# MKL28Z7 register map
Vendor: Freescale Semiconductor, Inc.; Series: Kinetis_L; File version: 1.6
CPU: CM0PLUS r0p0, little endian, no MPU, no FPU, VTOR, 2 interrupt priority bits
Registers are 32-bit, read-write, reset 0x0 unless marked. A register's access mark holds for its fields unless they carry their own. Offsets are from the block's base; [hi:lo] are bit positions; {n}, {i} and the like mark numbered series; 'fields as' and 'values as' point back to an identical list.

## NVIC0 — Nested Vectored Interrupt Controller
Base 0xE000E100
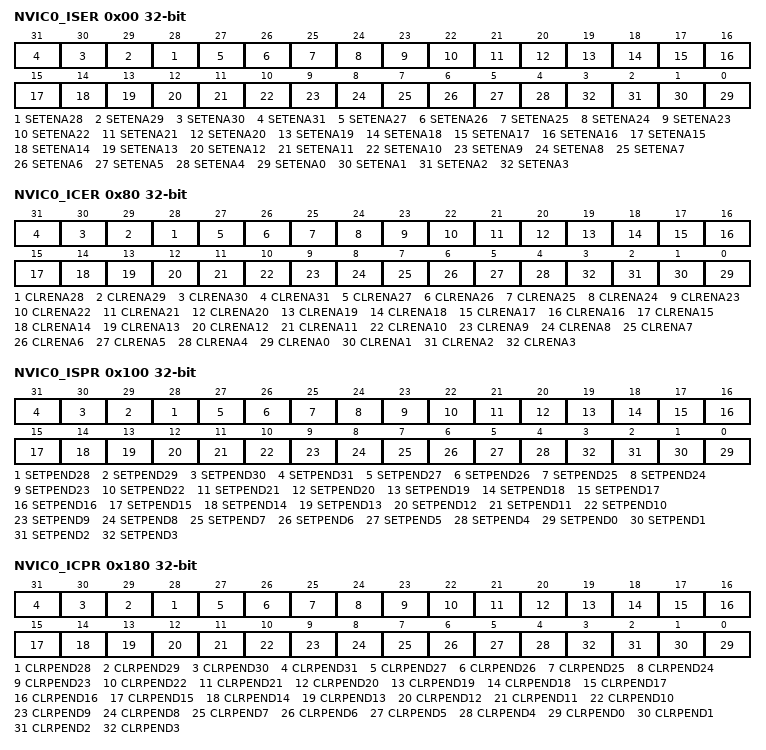
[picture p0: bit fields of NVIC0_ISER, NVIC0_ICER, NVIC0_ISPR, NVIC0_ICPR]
0x00 NVIC0_ISER — Interrupt Set Enable Register
  [n] SETENA{n} (n=28..31) — INTMUX0 channel {n-28} interrupt interrupt set-enable bit
    0=write: no effect; read: INTMUX0 channel {n-28} interrupt interrupt disabled; 1=write: enable INTMUX0 channel {n-28} interrupt interrupt; read: INTMUX0 channel {n-28} interrupt interrupt enabled
  [27] SETENA27 — RTC seconds interrupt set-enable bit
    0=write: no effect; read: RTC seconds interrupt disabled; 1=write: enable RTC seconds interrupt; read: RTC seconds interrupt enabled
  [26] SETENA26 — Low-Power Timer interrupt set-enable bit
    0=write: no effect; read: Low-Power Timer interrupt disabled; 1=write: enable Low-Power Timer interrupt; read: Low-Power Timer interrupt enabled
  [25] SETENA25 — Analog-to-Digital Converter 0 interrupt set-enable bit
    0=write: no effect; read: Analog-to-Digital Converter 0 interrupt disabled; 1=write: enable Analog-to-Digital Converter 0 interrupt; read: Analog-to-Digital Converter 0 interrupt enabled
  [24] SETENA24 — Universal Serial Bus interrupt set-enable bit
    0=write: no effect; read: Universal Serial Bus interrupt disabled; 1=write: enable Universal Serial Bus interrupt; read: Universal Serial Bus interrupt enabled
  [23] SETENA23 — Integrated interchip sound 0 interrupt set-enable bit
    0=write: no effect; read: Integrated interchip sound 0 interrupt disabled; 1=write: enable Integrated interchip sound 0 interrupt; read: Integrated interchip sound 0 interrupt enabled
  [22] SETENA22 — Low Leakage Wakeup 0 interrupt set-enable bit
    0=write: no effect; read: Low Leakage Wakeup 0 interrupt disabled; 1=write: enable Low Leakage Wakeup 0 interrupt; read: Low Leakage Wakeup 0 interrupt enabled
  [21] SETENA21 — PORTE Pin detect interrupt set-enable bit
    0=write: no effect; read: PORTE Pin detect interrupt disabled; 1=write: enable PORTE Pin detect interrupt; read: PORTE Pin detect interrupt enabled
  [20] SETENA20 — PORTD Pin detect interrupt set-enable bit
    0=write: no effect; read: PORTD Pin detect interrupt disabled; 1=write: enable PORTD Pin detect interrupt; read: PORTD Pin detect interrupt enabled
  [19] SETENA19 — PORTC Pin detect interrupt set-enable bit
    0=write: no effect; read: PORTC Pin detect interrupt disabled; 1=write: enable PORTC Pin detect interrupt; read: PORTC Pin detect interrupt enabled
  [18] SETENA18 — PORTB Pin detect interrupt set-enable bit
    0=write: no effect; read: PORTB Pin detect interrupt disabled; 1=write: enable PORTB Pin detect interrupt; read: PORTB Pin detect interrupt enabled
  [17] SETENA17 — PORTA Pin detect interrupt set-enable bit
    0=write: no effect; read: PORTA Pin detect interrupt disabled; 1=write: enable PORTA Pin detect interrupt; read: PORTA Pin detect interrupt enabled
  [16] SETENA16 — Reserved iv 32 interrupt set-enable bit
    0=write: no effect; read: Reserved iv 32 interrupt disabled; 1=write: enable Reserved iv 32 interrupt; read: Reserved iv 32 interrupt enabled
  [15] SETENA15 — Inter-Integrated Circuit 0 interrupt set-enable bit
    0=write: no effect; read: Inter-Integrated Circuit 0 interrupt disabled; 1=write: enable Inter-Integrated Circuit 0 interrupt; read: Inter-Integrated Circuit 0 interrupt enabled
  [14] SETENA14 — Inter-Integrated Circuit 0 interrupt set-enable bit
    values as SETENA15
  [13] SETENA13 — LPUART1 status and error interrupt set-enable bit
    0=write: no effect; read: LPUART1 status and error interrupt disabled; 1=write: enable LPUART1 status and error interrupt; read: LPUART1 status and error interrupt enabled
  [12] SETENA12 — LPUART0 status and error interrupt set-enable bit
    0=write: no effect; read: LPUART0 status and error interrupt disabled; 1=write: enable LPUART0 status and error interrupt; read: LPUART0 status and error interrupt enabled
  [11] SETENA11 — Serial Peripheral Interface 1 interrupt set-enable bit
    0=write: no effect; read: Serial Peripheral Interface 1 interrupt disabled; 1=write: enable Serial Peripheral Interface 1 interrupt; read: Serial Peripheral Interface 1 interrupt enabled
  [10] SETENA10 — Serial Peripheral Interface 0 interrupt set-enable bit
    0=write: no effect; read: Serial Peripheral Interface 0 interrupt disabled; 1=write: enable Serial Peripheral Interface 0 interrupt; read: Serial Peripheral Interface 0 interrupt enabled
  [9] SETENA9 — Low Power Periodic Interrupt Timer interrupt set-enable bit
    0=write: no effect; read: Low Power Periodic Interrupt Timer interrupt disabled; 1=write: enable Low Power Periodic Interrupt Timer interrupt; read: Low Power Periodic Interrupt Timer interrupt enabled
  [8] SETENA8 — Timer/PWM module 2 interrupt set-enable bit
    0=write: no effect; read: Timer/PWM module 2 interrupt disabled; 1=write: enable Timer/PWM module 2 interrupt; read: Timer/PWM module 2 interrupt enabled
  [7] SETENA7 — Timer/PWM module 1 interrupt set-enable bit
    0=write: no effect; read: Timer/PWM module 1 interrupt disabled; 1=write: enable Timer/PWM module 1 interrupt; read: Timer/PWM module 1 interrupt enabled
  [6] SETENA6 — Timer/PWM module 0 interrupt set-enable bit
    0=write: no effect; read: Timer/PWM module 0 interrupt disabled; 1=write: enable Timer/PWM module 0 interrupt; read: Timer/PWM module 0 interrupt enabled
  [5] SETENA5 — FLEXIO0 interrupt set-enable bit
    0=write: no effect; read: FLEXIO0 interrupt disabled; 1=write: enable FLEXIO0 interrupt; read: FLEXIO0 interrupt enabled
  [4] SETENA4 — CTI0 or DMA0 error interrupt set-enable bit
    0=write: no effect; read: CTI0 or DMA0 error interrupt disabled; 1=write: enable CTI0 or DMA0 error interrupt; read: CTI0 or DMA0 error interrupt enabled
  [n] SETENA{n} (n=0..3) — DMA0 channel {n}/{n+4} transfer complete interrupt set-enable bit
    0=write: no effect; read: DMA0 channel {n}/{n+4} transfer complete interrupt disabled; 1=write: enable DMA0 channel {n}/{n+4} transfer complete interrupt; read: DMA0 channel {n}/{n+4} transfer complete interrupt enabled
0x80 NVIC0_ICER — Interrupt Clear Enable Register
  [n] CLRENA{n} (n=28..31) — INTMUX0 channel {n-28} interrupt interrupt clear-enable bit
    0=write: no effect; read: INTMUX0 channel {n-28} interrupt interrupt disabled; 1=write: disable INTMUX0 channel {n-28} interrupt interrupt; read: INTMUX0 channel {n-28} interrupt interrupt enabled
  [27] CLRENA27 — RTC seconds interrupt clear-enable bit
    0=write: no effect; read: RTC seconds interrupt disabled; 1=write: disable RTC seconds interrupt; read: RTC seconds interrupt enabled
  [26] CLRENA26 — Low-Power Timer interrupt clear-enable bit
    0=write: no effect; read: Low-Power Timer interrupt disabled; 1=write: disable Low-Power Timer interrupt; read: Low-Power Timer interrupt enabled
  [25] CLRENA25 — Analog-to-Digital Converter 0 interrupt clear-enable bit
    0=write: no effect; read: Analog-to-Digital Converter 0 interrupt disabled; 1=write: disable Analog-to-Digital Converter 0 interrupt; read: Analog-to-Digital Converter 0 interrupt enabled
  [24] CLRENA24 — Universal Serial Bus interrupt clear-enable bit
    0=write: no effect; read: Universal Serial Bus interrupt disabled; 1=write: disable Universal Serial Bus interrupt; read: Universal Serial Bus interrupt enabled
  [23] CLRENA23 — Integrated interchip sound 0 interrupt clear-enable bit
    0=write: no effect; read: Integrated interchip sound 0 interrupt disabled; 1=write: disable Integrated interchip sound 0 interrupt; read: Integrated interchip sound 0 interrupt enabled
  [22] CLRENA22 — Low Leakage Wakeup 0 interrupt clear-enable bit
    0=write: no effect; read: Low Leakage Wakeup 0 interrupt disabled; 1=write: disable Low Leakage Wakeup 0 interrupt; read: Low Leakage Wakeup 0 interrupt enabled
  [21] CLRENA21 — PORTE Pin detect interrupt clear-enable bit
    0=write: no effect; read: PORTE Pin detect interrupt disabled; 1=write: disable PORTE Pin detect interrupt; read: PORTE Pin detect interrupt enabled
  [20] CLRENA20 — PORTD Pin detect interrupt clear-enable bit
    0=write: no effect; read: PORTD Pin detect interrupt disabled; 1=write: disable PORTD Pin detect interrupt; read: PORTD Pin detect interrupt enabled
  [19] CLRENA19 — PORTC Pin detect interrupt clear-enable bit
    0=write: no effect; read: PORTC Pin detect interrupt disabled; 1=write: disable PORTC Pin detect interrupt; read: PORTC Pin detect interrupt enabled
  [18] CLRENA18 — PORTB Pin detect interrupt clear-enable bit
    0=write: no effect; read: PORTB Pin detect interrupt disabled; 1=write: disable PORTB Pin detect interrupt; read: PORTB Pin detect interrupt enabled
  [17] CLRENA17 — PORTA Pin detect interrupt clear-enable bit
    0=write: no effect; read: PORTA Pin detect interrupt disabled; 1=write: disable PORTA Pin detect interrupt; read: PORTA Pin detect interrupt enabled
  [16] CLRENA16 — Reserved iv 32 interrupt clear-enable bit
    0=write: no effect; read: Reserved iv 32 interrupt disabled; 1=write: disable Reserved iv 32 interrupt; read: Reserved iv 32 interrupt enabled
  [15] CLRENA15 — Inter-Integrated Circuit 0 interrupt clear-enable bit
    0=write: no effect; read: Inter-Integrated Circuit 0 interrupt disabled; 1=write: disable Inter-Integrated Circuit 0 interrupt; read: Inter-Integrated Circuit 0 interrupt enabled
  [14] CLRENA14 — Inter-Integrated Circuit 0 interrupt clear-enable bit
    values as CLRENA15
  [13] CLRENA13 — LPUART1 status and error interrupt clear-enable bit
    0=write: no effect; read: LPUART1 status and error interrupt disabled; 1=write: disable LPUART1 status and error interrupt; read: LPUART1 status and error interrupt enabled
  [12] CLRENA12 — LPUART0 status and error interrupt clear-enable bit
    0=write: no effect; read: LPUART0 status and error interrupt disabled; 1=write: disable LPUART0 status and error interrupt; read: LPUART0 status and error interrupt enabled
  [11] CLRENA11 — Serial Peripheral Interface 1 interrupt clear-enable bit
    0=write: no effect; read: Serial Peripheral Interface 1 interrupt disabled; 1=write: disable Serial Peripheral Interface 1 interrupt; read: Serial Peripheral Interface 1 interrupt enabled
  [10] CLRENA10 — Serial Peripheral Interface 0 interrupt clear-enable bit
    0=write: no effect; read: Serial Peripheral Interface 0 interrupt disabled; 1=write: disable Serial Peripheral Interface 0 interrupt; read: Serial Peripheral Interface 0 interrupt enabled
  [9] CLRENA9 — Low Power Periodic Interrupt Timer interrupt clear-enable bit
    0=write: no effect; read: Low Power Periodic Interrupt Timer interrupt disabled; 1=write: disable Low Power Periodic Interrupt Timer interrupt; read: Low Power Periodic Interrupt Timer interrupt enabled
  [8] CLRENA8 — Timer/PWM module 2 interrupt clear-enable bit
    0=write: no effect; read: Timer/PWM module 2 interrupt disabled; 1=write: disable Timer/PWM module 2 interrupt; read: Timer/PWM module 2 interrupt enabled
  [7] CLRENA7 — Timer/PWM module 1 interrupt clear-enable bit
    0=write: no effect; read: Timer/PWM module 1 interrupt disabled; 1=write: disable Timer/PWM module 1 interrupt; read: Timer/PWM module 1 interrupt enabled
  [6] CLRENA6 — Timer/PWM module 0 interrupt clear-enable bit
    0=write: no effect; read: Timer/PWM module 0 interrupt disabled; 1=write: disable Timer/PWM module 0 interrupt; read: Timer/PWM module 0 interrupt enabled
  [5] CLRENA5 — FLEXIO0 interrupt clear-enable bit
    0=write: no effect; read: FLEXIO0 interrupt disabled; 1=write: disable FLEXIO0 interrupt; read: FLEXIO0 interrupt enabled
  [4] CLRENA4 — CTI0 or DMA0 error interrupt clear-enable bit
    0=write: no effect; read: CTI0 or DMA0 error interrupt disabled; 1=write: disable CTI0 or DMA0 error interrupt; read: CTI0 or DMA0 error interrupt enabled
  [n] CLRENA{n} (n=0..3) — DMA0 channel {n}/{n+4} transfer complete interrupt clear-enable bit
    0=write: no effect; read: DMA0 channel {n}/{n+4} transfer complete interrupt disabled; 1=write: disable DMA0 channel {n}/{n+4} transfer complete interrupt; read: DMA0 channel {n}/{n+4} transfer complete interrupt enabled
0x100 NVIC0_ISPR — Interrupt Set Pending Register
  [n] SETPEND{n} (n=28..31) — INTMUX0 channel {n-28} interrupt interrupt set-pending bit
    0=write: no effect; read: INTMUX0 channel {n-28} interrupt interrupt is not pending; 1=write: changes the INTMUX0 channel {n-28} interrupt interrupt state to pending; read: INTMUX0 channel {n-28} interrupt interrupt is pending
  [27] SETPEND27 — RTC seconds interrupt set-pending bit
    0=write: no effect; read: RTC seconds interrupt is not pending; 1=write: changes the RTC seconds interrupt state to pending; read: RTC seconds interrupt is pending
  [26] SETPEND26 — Low-Power Timer interrupt set-pending bit
    0=write: no effect; read: Low-Power Timer interrupt is not pending; 1=write: changes the Low-Power Timer interrupt state to pending; read: Low-Power Timer interrupt is pending
  [25] SETPEND25 — Analog-to-Digital Converter 0 interrupt set-pending bit
    0=write: no effect; read: Analog-to-Digital Converter 0 interrupt is not pending; 1=write: changes the Analog-to-Digital Converter 0 interrupt state to pending; read: Analog-to-Digital Converter 0 interrupt is pending
  [24] SETPEND24 — Universal Serial Bus interrupt set-pending bit
    0=write: no effect; read: Universal Serial Bus interrupt is not pending; 1=write: changes the Universal Serial Bus interrupt state to pending; read: Universal Serial Bus interrupt is pending
  [23] SETPEND23 — Integrated interchip sound 0 interrupt set-pending bit
    0=write: no effect; read: Integrated interchip sound 0 interrupt is not pending; 1=write: changes the Integrated interchip sound 0 interrupt state to pending; read: Integrated interchip sound 0 interrupt is pending
  [22] SETPEND22 — Low Leakage Wakeup 0 interrupt set-pending bit
    0=write: no effect; read: Low Leakage Wakeup 0 interrupt is not pending; 1=write: changes the Low Leakage Wakeup 0 interrupt state to pending; read: Low Leakage Wakeup 0 interrupt is pending
  [21] SETPEND21 — PORTE Pin detect interrupt set-pending bit
    0=write: no effect; read: PORTE Pin detect interrupt is not pending; 1=write: changes the PORTE Pin detect interrupt state to pending; read: PORTE Pin detect interrupt is pending
  [20] SETPEND20 — PORTD Pin detect interrupt set-pending bit
    0=write: no effect; read: PORTD Pin detect interrupt is not pending; 1=write: changes the PORTD Pin detect interrupt state to pending; read: PORTD Pin detect interrupt is pending
  [19] SETPEND19 — PORTC Pin detect interrupt set-pending bit
    0=write: no effect; read: PORTC Pin detect interrupt is not pending; 1=write: changes the PORTC Pin detect interrupt state to pending; read: PORTC Pin detect interrupt is pending
  [18] SETPEND18 — PORTB Pin detect interrupt set-pending bit
    0=write: no effect; read: PORTB Pin detect interrupt is not pending; 1=write: changes the PORTB Pin detect interrupt state to pending; read: PORTB Pin detect interrupt is pending
  [17] SETPEND17 — PORTA Pin detect interrupt set-pending bit
    0=write: no effect; read: PORTA Pin detect interrupt is not pending; 1=write: changes the PORTA Pin detect interrupt state to pending; read: PORTA Pin detect interrupt is pending
  [16] SETPEND16 — Reserved iv 32 interrupt set-pending bit
    0=write: no effect; read: Reserved iv 32 interrupt is not pending; 1=write: changes the Reserved iv 32 interrupt state to pending; read: Reserved iv 32 interrupt is pending
  [15] SETPEND15 — Inter-Integrated Circuit 0 interrupt set-pending bit
    0=write: no effect; read: Inter-Integrated Circuit 0 interrupt is not pending; 1=write: changes the Inter-Integrated Circuit 0 interrupt state to pending; read: Inter-Integrated Circuit 0 interrupt is pending
  [14] SETPEND14 — Inter-Integrated Circuit 0 interrupt set-pending bit
    values as SETPEND15
  [13] SETPEND13 — LPUART1 status and error interrupt set-pending bit
    0=write: no effect; read: LPUART1 status and error interrupt is not pending; 1=write: changes the LPUART1 status and error interrupt state to pending; read: LPUART1 status and error interrupt is pending
  [12] SETPEND12 — LPUART0 status and error interrupt set-pending bit
    0=write: no effect; read: LPUART0 status and error interrupt is not pending; 1=write: changes the LPUART0 status and error interrupt state to pending; read: LPUART0 status and error interrupt is pending
  [11] SETPEND11 — Serial Peripheral Interface 1 interrupt set-pending bit
    0=write: no effect; read: Serial Peripheral Interface 1 interrupt is not pending; 1=write: changes the Serial Peripheral Interface 1 interrupt state to pending; read: Serial Peripheral Interface 1 interrupt is pending
  [10] SETPEND10 — Serial Peripheral Interface 0 interrupt set-pending bit
    0=write: no effect; read: Serial Peripheral Interface 0 interrupt is not pending; 1=write: changes the Serial Peripheral Interface 0 interrupt state to pending; read: Serial Peripheral Interface 0 interrupt is pending
  [9] SETPEND9 — Low Power Periodic Interrupt Timer interrupt set-pending bit
    0=write: no effect; read: Low Power Periodic Interrupt Timer interrupt is not pending; 1=write: changes the Low Power Periodic Interrupt Timer interrupt state to pending; read: Low Power Periodic Interrupt Timer interrupt is pending
  [8] SETPEND8 — Timer/PWM module 2 interrupt set-pending bit
    0=write: no effect; read: Timer/PWM module 2 interrupt is not pending; 1=write: changes the Timer/PWM module 2 interrupt state to pending; read: Timer/PWM module 2 interrupt is pending
  [7] SETPEND7 — Timer/PWM module 1 interrupt set-pending bit
    0=write: no effect; read: Timer/PWM module 1 interrupt is not pending; 1=write: changes the Timer/PWM module 1 interrupt state to pending; read: Timer/PWM module 1 interrupt is pending
  [6] SETPEND6 — Timer/PWM module 0 interrupt set-pending bit
    0=write: no effect; read: Timer/PWM module 0 interrupt is not pending; 1=write: changes the Timer/PWM module 0 interrupt state to pending; read: Timer/PWM module 0 interrupt is pending
  [5] SETPEND5 — FLEXIO0 interrupt set-pending bit
    0=write: no effect; read: FLEXIO0 interrupt is not pending; 1=write: changes the FLEXIO0 interrupt state to pending; read: FLEXIO0 interrupt is pending
  [4] SETPEND4 — CTI0 or DMA0 error interrupt set-pending bit
    0=write: no effect; read: CTI0 or DMA0 error interrupt is not pending; 1=write: changes the CTI0 or DMA0 error interrupt state to pending; read: CTI0 or DMA0 error interrupt is pending
  [n] SETPEND{n} (n=0..3) — DMA0 channel {n}/{n+4} transfer complete interrupt set-pending bit
    0=write: no effect; read: DMA0 channel {n}/{n+4} transfer complete interrupt is not pending; 1=write: changes the DMA0 channel {n}/{n+4} transfer complete interrupt state to pending; read: DMA0 channel {n}/{n+4} transfer complete interrupt is pending
0x180 NVIC0_ICPR — Interrupt Clear Pending Register
  [n] CLRPEND{n} (n=28..31) — INTMUX0 channel {n-28} interrupt interrupt clear-pending bit
    0=write: no effect; read: INTMUX0 channel {n-28} interrupt interrupt is not pending; 1=write: removes pending state from the INTMUX0 channel {n-28} interrupt interrupt; read: INTMUX0 channel {n-28} interrupt interrupt is pending
  [27] CLRPEND27 — RTC seconds interrupt clear-pending bit
    0=write: no effect; read: RTC seconds interrupt is not pending; 1=write: removes pending state from the RTC seconds interrupt; read: RTC seconds interrupt is pending
  [26] CLRPEND26 — Low-Power Timer interrupt clear-pending bit
    0=write: no effect; read: Low-Power Timer interrupt is not pending; 1=write: removes pending state from the Low-Power Timer interrupt; read: Low-Power Timer interrupt is pending
  [25] CLRPEND25 — Analog-to-Digital Converter 0 interrupt clear-pending bit
    0=write: no effect; read: Analog-to-Digital Converter 0 interrupt is not pending; 1=write: removes pending state from the Analog-to-Digital Converter 0 interrupt; read: Analog-to-Digital Converter 0 interrupt is pending
  [24] CLRPEND24 — Universal Serial Bus interrupt clear-pending bit
    0=write: no effect; read: Universal Serial Bus interrupt is not pending; 1=write: removes pending state from the Universal Serial Bus interrupt; read: Universal Serial Bus interrupt is pending
  [23] CLRPEND23 — Integrated interchip sound 0 interrupt clear-pending bit
    0=write: no effect; read: Integrated interchip sound 0 interrupt is not pending; 1=write: removes pending state from the Integrated interchip sound 0 interrupt; read: Integrated interchip sound 0 interrupt is pending
  [22] CLRPEND22 — Low Leakage Wakeup 0 interrupt clear-pending bit
    0=write: no effect; read: Low Leakage Wakeup 0 interrupt is not pending; 1=write: removes pending state from the Low Leakage Wakeup 0 interrupt; read: Low Leakage Wakeup 0 interrupt is pending
  [21] CLRPEND21 — PORTE Pin detect interrupt clear-pending bit
    0=write: no effect; read: PORTE Pin detect interrupt is not pending; 1=write: removes pending state from the PORTE Pin detect interrupt; read: PORTE Pin detect interrupt is pending
  [20] CLRPEND20 — PORTD Pin detect interrupt clear-pending bit
    0=write: no effect; read: PORTD Pin detect interrupt is not pending; 1=write: removes pending state from the PORTD Pin detect interrupt; read: PORTD Pin detect interrupt is pending
  [19] CLRPEND19 — PORTC Pin detect interrupt clear-pending bit
    0=write: no effect; read: PORTC Pin detect interrupt is not pending; 1=write: removes pending state from the PORTC Pin detect interrupt; read: PORTC Pin detect interrupt is pending
  [18] CLRPEND18 — PORTB Pin detect interrupt clear-pending bit
    0=write: no effect; read: PORTB Pin detect interrupt is not pending; 1=write: removes pending state from the PORTB Pin detect interrupt; read: PORTB Pin detect interrupt is pending
  [17] CLRPEND17 — PORTA Pin detect interrupt clear-pending bit
    0=write: no effect; read: PORTA Pin detect interrupt is not pending; 1=write: removes pending state from the PORTA Pin detect interrupt; read: PORTA Pin detect interrupt is pending
  [16] CLRPEND16 — Reserved iv 32 interrupt clear-pending bit
    0=write: no effect; read: Reserved iv 32 interrupt is not pending; 1=write: removes pending state from the Reserved iv 32 interrupt; read: Reserved iv 32 interrupt is pending
  [15] CLRPEND15 — Inter-Integrated Circuit 0 interrupt clear-pending bit
    0=write: no effect; read: Inter-Integrated Circuit 0 interrupt is not pending; 1=write: removes pending state from the Inter-Integrated Circuit 0 interrupt; read: Inter-Integrated Circuit 0 interrupt is pending
  [14] CLRPEND14 — Inter-Integrated Circuit 0 interrupt clear-pending bit
    values as CLRPEND15
  [13] CLRPEND13 — LPUART1 status and error interrupt clear-pending bit
    0=write: no effect; read: LPUART1 status and error interrupt is not pending; 1=write: removes pending state from the LPUART1 status and error interrupt; read: LPUART1 status and error interrupt is pending
  [12] CLRPEND12 — LPUART0 status and error interrupt clear-pending bit
    0=write: no effect; read: LPUART0 status and error interrupt is not pending; 1=write: removes pending state from the LPUART0 status and error interrupt; read: LPUART0 status and error interrupt is pending
  [11] CLRPEND11 — Serial Peripheral Interface 1 interrupt clear-pending bit
    0=write: no effect; read: Serial Peripheral Interface 1 interrupt is not pending; 1=write: removes pending state from the Serial Peripheral Interface 1 interrupt; read: Serial Peripheral Interface 1 interrupt is pending
  [10] CLRPEND10 — Serial Peripheral Interface 0 interrupt clear-pending bit
    0=write: no effect; read: Serial Peripheral Interface 0 interrupt is not pending; 1=write: removes pending state from the Serial Peripheral Interface 0 interrupt; read: Serial Peripheral Interface 0 interrupt is pending
  [9] CLRPEND9 — Low Power Periodic Interrupt Timer interrupt clear-pending bit
    0=write: no effect; read: Low Power Periodic Interrupt Timer interrupt is not pending; 1=write: removes pending state from the Low Power Periodic Interrupt Timer interrupt; read: Low Power Periodic Interrupt Timer interrupt is pending
  [8] CLRPEND8 — Timer/PWM module 2 interrupt clear-pending bit
    0=write: no effect; read: Timer/PWM module 2 interrupt is not pending; 1=write: removes pending state from the Timer/PWM module 2 interrupt; read: Timer/PWM module 2 interrupt is pending
  [7] CLRPEND7 — Timer/PWM module 1 interrupt clear-pending bit
    0=write: no effect; read: Timer/PWM module 1 interrupt is not pending; 1=write: removes pending state from the Timer/PWM module 1 interrupt; read: Timer/PWM module 1 interrupt is pending
  [6] CLRPEND6 — Timer/PWM module 0 interrupt clear-pending bit
    0=write: no effect; read: Timer/PWM module 0 interrupt is not pending; 1=write: removes pending state from the Timer/PWM module 0 interrupt; read: Timer/PWM module 0 interrupt is pending
  [5] CLRPEND5 — FLEXIO0 interrupt clear-pending bit
    0=write: no effect; read: FLEXIO0 interrupt is not pending; 1=write: removes pending state from the FLEXIO0 interrupt; read: FLEXIO0 interrupt is pending
  [4] CLRPEND4 — CTI0 or DMA0 error interrupt clear-pending bit
    0=write: no effect; read: CTI0 or DMA0 error interrupt is not pending; 1=write: removes pending state from the CTI0 or DMA0 error interrupt; read: CTI0 or DMA0 error interrupt is pending
  [n] CLRPEND{n} (n=0..3) — DMA0 channel {n}/{n+4} transfer complete interrupt clear-pending bit
    0=write: no effect; read: DMA0 channel {n}/{n+4} transfer complete interrupt is not pending; 1=write: removes pending state from the DMA0 channel {n}/{n+4} transfer complete interrupt; read: DMA0 channel {n}/{n+4} transfer complete interrupt is pending
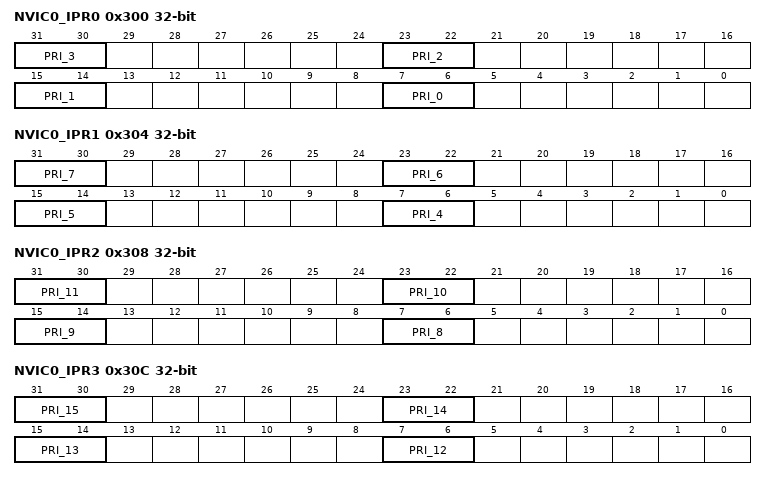
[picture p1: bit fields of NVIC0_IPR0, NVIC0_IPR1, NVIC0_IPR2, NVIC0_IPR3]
0x300 NVIC0_IPR0 — Interrupt Priority Register 0
  [8n+7:8n+6] PRI_{n} (n=0..3) — Priority of the DMA0 channel {n}/{n+4} transfer complete interrupt
0x304 NVIC0_IPR1 — Interrupt Priority Register 1
  [31:30] PRI_7 — Priority of the Timer/PWM module 1 interrupt
  [23:22] PRI_6 — Priority of the Timer/PWM module 0 interrupt
  [15:14] PRI_5 — Priority of the FLEXIO0 interrupt
  [7:6] PRI_4 — Priority of the CTI0 or DMA0 error interrupt
0x308 NVIC0_IPR2 — Interrupt Priority Register 2
  [31:30] PRI_11 — Priority of the Serial Peripheral Interface 1 interrupt
  [23:22] PRI_10 — Priority of the Serial Peripheral Interface 0 interrupt
  [15:14] PRI_9 — Priority of the Low Power Periodic Interrupt Timer interrupt
  [7:6] PRI_8 — Priority of the Timer/PWM module 2 interrupt
0x30C NVIC0_IPR3 — Interrupt Priority Register 3
  [31:30] PRI_15 — Priority of the Inter-Integrated Circuit 0 interrupt
  [23:22] PRI_14 — Priority of the Inter-Integrated Circuit 0 interrupt
  [15:14] PRI_13 — Priority of the LPUART1 status and error interrupt
  [7:6] PRI_12 — Priority of the LPUART0 status and error interrupt
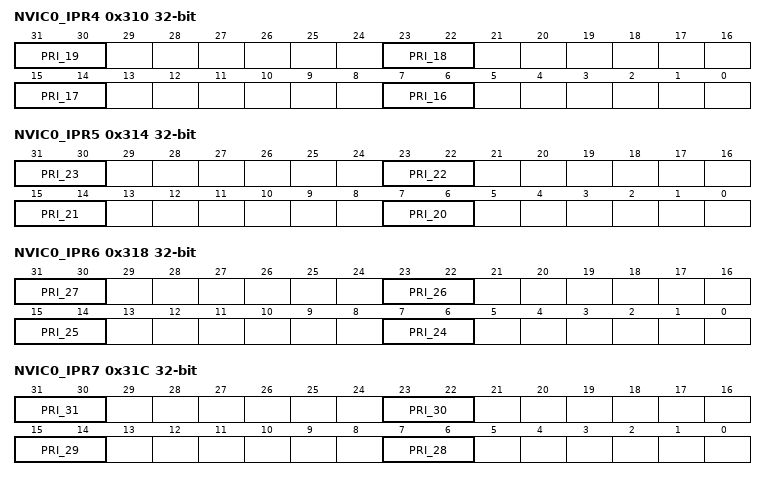
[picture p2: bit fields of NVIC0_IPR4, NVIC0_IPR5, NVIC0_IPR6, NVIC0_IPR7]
0x310 NVIC0_IPR4 — Interrupt Priority Register 4
  [31:30] PRI_19 — Priority of the PORTC Pin detect interrupt
  [23:22] PRI_18 — Priority of the PORTB Pin detect interrupt
  [15:14] PRI_17 — Priority of the PORTA Pin detect interrupt
  [7:6] PRI_16 — Priority of the Reserved iv 32 interrupt
0x314 NVIC0_IPR5 — Interrupt Priority Register 5
  [31:30] PRI_23 — Priority of the Integrated interchip sound 0 interrupt
  [23:22] PRI_22 — Priority of the Low Leakage Wakeup 0 interrupt
  [15:14] PRI_21 — Priority of the PORTE Pin detect interrupt
  [7:6] PRI_20 — Priority of the PORTD Pin detect interrupt
0x318 NVIC0_IPR6 — Interrupt Priority Register 6
  [31:30] PRI_27 — Priority of the RTC seconds interrupt
  [23:22] PRI_26 — Priority of the Low-Power Timer interrupt
  [15:14] PRI_25 — Priority of the Analog-to-Digital Converter 0 interrupt
  [7:6] PRI_24 — Priority of the Universal Serial Bus interrupt
0x31C NVIC0_IPR7 — Interrupt Priority Register 7
  [8n-217:8n-218] PRI_{n} (n=28..31) — Priority of the INTMUX0 channel {n-28} interrupt interrupt
